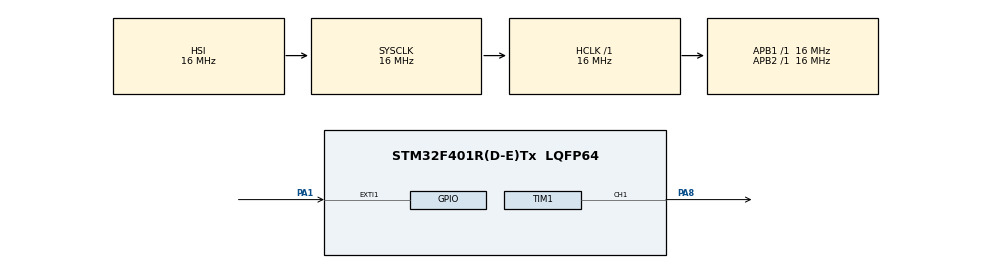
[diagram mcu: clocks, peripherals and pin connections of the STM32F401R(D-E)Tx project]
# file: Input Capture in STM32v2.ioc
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Mcu.Family=STM32F4
Mcu.Name=STM32F401R(D-E)Tx
Mcu.Package=LQFP64
NVIC.EXTI1_IRQn=true\:0\:0\:false\:false\:true\:true\:true\:true
NVIC.PriorityGroup=NVIC_PRIORITYGROUP_4
NVIC.TIM2_IRQn=true\:0\:0\:false\:false\:true\:true\:true\:true
PA1.GPIO_PuPd=GPIO_PULLDOWN
PA1.Signal=GPXTI1
PA8.Signal=S_TIM1_CH1
ProjectManager.HeapSize=0x200
ProjectManager.StackSize=0x400
ProjectManager.TargetToolchain=STM32CubeIDE
RCC.AHBFreq_Value=16000000
RCC.APB1Freq_Value=16000000
RCC.APB1TimFreq_Value=16000000
RCC.APB2Freq_Value=16000000
RCC.APB2TimFreq_Value=16000000
RCC.CortexFreq_Value=16000000
RCC.HCLKFreq_Value=16000000
RCC.HSE_VALUE=25000000
RCC.HSI_VALUE=16000000
RCC.LSE_VALUE=32768
RCC.SYSCLKFreq_VALUE=16000000
RCC.VCOOutputFreq_Value=192000000
SH.S_TIM1_CH1.0=TIM1_CH1,PWM Generation1 CH1
TIM1.Channel-PWM\ Generation1\ CH1=TIM_CHANNEL_1
TIM1.Period=100-1
TIM1.Prescaler=16-1
TIM2.Period=9999
TIM2.Prescaler=1600-1
VP_TIM1_VS_ClockSourceINT.Mode=Internal
VP_TIM2_VS_ClockSourceINT.Mode=Internal
board=custom

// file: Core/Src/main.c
/* USER CODE BEGIN Header */
/**
  ******************************************************************************
  * @file           : main.c
  * @brief          : Main program body
  ******************************************************************************
  * @attention
  *
  * Copyright (c) 2023 STMicroelectronics.
  * All rights reserved.
  *
  * This software is licensed under terms that can be found in the LICENSE file
  * in the root directory of this software component.
  * If no LICENSE file comes with this software, it is provided AS-IS.
  *
  ******************************************************************************
  */
/* USER CODE END Header */
#include "main.h"

TIM_HandleTypeDef htim1;
TIM_HandleTypeDef htim2;

/* USER CODE BEGIN PV */
uint32_t count = 0;

/* USER CODE END PV */

void SystemClock_Config(void);
static void MX_GPIO_Init(void);
static void MX_TIM1_Init(void);
static void MX_TIM2_Init(void);

/* USER CODE BEGIN 0 */
void HAL_TIM_PeriodElapsedCallback(TIM_HandleTypeDef *htim){

	if(htim == &htim2){
		HAL_NVIC_DisableIRQ(EXTI1_IRQn);
	}
}

__weak void HAL_GPIO_EXTI_Callback(uint16_t GPIO_Pin){
	if(GPIO_Pin == GPIO_PIN_1){
	count++;
	}
}

/* USER CODE END 0 */

int main(void)
{

  /* MCU Configuration--------------------------------------------------------*/

  /* Reset of all peripherals, Initializes the Flash interface and the Systick. */
  HAL_Init();

  /* Configure the system clock */
  SystemClock_Config();

  /* Initialize all configured peripherals */
  MX_GPIO_Init();
  MX_TIM1_Init();
  MX_TIM2_Init();
  /* USER CODE BEGIN 2 */
  TIM1->CCR1 = 50;
  HAL_TIM_PWM_Start(&htim1, TIM_CHANNEL_1);
  HAL_Delay(1000);
  HAL_TIM_Base_Start_IT(&htim2);
  HAL_NVIC_EnableIRQ(EXTI1_IRQn);
  //__HAL_TIM_DISABLE_IT(&htim2, TIM_IT_UPDATE);

  /* USER CODE END 2 */

  /* Infinite loop */
  while (1)
  {

  }
}

void SystemClock_Config(void)
{
  RCC_OscInitTypeDef RCC_OscInitStruct = {0};
  RCC_ClkInitTypeDef RCC_ClkInitStruct = {0};

  /** Configure the main internal regulator output voltage
  */
  __HAL_RCC_PWR_CLK_ENABLE();
  __HAL_PWR_VOLTAGESCALING_CONFIG(PWR_REGULATOR_VOLTAGE_SCALE2);

  /** Initializes the RCC Oscillators according to the specified parameters
  * in the RCC_OscInitTypeDef structure.
  */
  RCC_OscInitStruct.OscillatorType = RCC_OSCILLATORTYPE_HSI;
  RCC_OscInitStruct.HSIState = RCC_HSI_ON;
  RCC_OscInitStruct.HSICalibrationValue = RCC_HSICALIBRATION_DEFAULT;
  RCC_OscInitStruct.PLL.PLLState = RCC_PLL_NONE;
  if (HAL_RCC_OscConfig(&RCC_OscInitStruct) != HAL_OK)
  {
    Error_Handler();
  }

  /** Initializes the CPU, AHB and APB buses clocks
  */
  RCC_ClkInitStruct.ClockType = RCC_CLOCKTYPE_HCLK|RCC_CLOCKTYPE_SYSCLK
                              |RCC_CLOCKTYPE_PCLK1|RCC_CLOCKTYPE_PCLK2;
  RCC_ClkInitStruct.SYSCLKSource = RCC_SYSCLKSOURCE_HSI;
  RCC_ClkInitStruct.AHBCLKDivider = RCC_SYSCLK_DIV1;
  RCC_ClkInitStruct.APB1CLKDivider = RCC_HCLK_DIV1;
  RCC_ClkInitStruct.APB2CLKDivider = RCC_HCLK_DIV1;

  if (HAL_RCC_ClockConfig(&RCC_ClkInitStruct, FLASH_LATENCY_0) != HAL_OK)
  {
    Error_Handler();
  }
}

static void MX_TIM1_Init(void)
{

  TIM_ClockConfigTypeDef sClockSourceConfig = {0};
  TIM_MasterConfigTypeDef sMasterConfig = {0};
  TIM_OC_InitTypeDef sConfigOC = {0};
  TIM_BreakDeadTimeConfigTypeDef sBreakDeadTimeConfig = {0};

  htim1.Instance = TIM1;
  htim1.Init.Prescaler = 1-1;
  htim1.Init.CounterMode = TIM_COUNTERMODE_UP;
  htim1.Init.Period = 81-1;
  htim1.Init.ClockDivision = TIM_CLOCKDIVISION_DIV1;
  htim1.Init.RepetitionCounter = 0;
  htim1.Init.AutoReloadPreload = TIM_AUTORELOAD_PRELOAD_DISABLE;
  if (HAL_TIM_Base_Init(&htim1) != HAL_OK)
  {
    Error_Handler();
  }
  sClockSourceConfig.ClockSource = TIM_CLOCKSOURCE_INTERNAL;
  if (HAL_TIM_ConfigClockSource(&htim1, &sClockSourceConfig) != HAL_OK)
  {
    Error_Handler();
  }
  if (HAL_TIM_PWM_Init(&htim1) != HAL_OK)
  {
    Error_Handler();
  }
  sMasterConfig.MasterOutputTrigger = TIM_TRGO_RESET;
  sMasterConfig.MasterSlaveMode = TIM_MASTERSLAVEMODE_DISABLE;
  if (HAL_TIMEx_MasterConfigSynchronization(&htim1, &sMasterConfig) != HAL_OK)
  {
    Error_Handler();
  }
  sConfigOC.OCMode = TIM_OCMODE_PWM1;
  sConfigOC.Pulse = 0;
  sConfigOC.OCPolarity = TIM_OCPOLARITY_HIGH;
  sConfigOC.OCNPolarity = TIM_OCNPOLARITY_HIGH;
  sConfigOC.OCFastMode = TIM_OCFAST_DISABLE;
  sConfigOC.OCIdleState = TIM_OCIDLESTATE_RESET;
  sConfigOC.OCNIdleState = TIM_OCNIDLESTATE_RESET;
  if (HAL_TIM_PWM_ConfigChannel(&htim1, &sConfigOC, TIM_CHANNEL_1) != HAL_OK)
  {
    Error_Handler();
  }
  sBreakDeadTimeConfig.OffStateRunMode = TIM_OSSR_DISABLE;
  sBreakDeadTimeConfig.OffStateIDLEMode = TIM_OSSI_DISABLE;
  sBreakDeadTimeConfig.LockLevel = TIM_LOCKLEVEL_OFF;
  sBreakDeadTimeConfig.DeadTime = 0;
  sBreakDeadTimeConfig.BreakState = TIM_BREAK_DISABLE;
  sBreakDeadTimeConfig.BreakPolarity = TIM_BREAKPOLARITY_HIGH;
  sBreakDeadTimeConfig.AutomaticOutput = TIM_AUTOMATICOUTPUT_DISABLE;
  if (HAL_TIMEx_ConfigBreakDeadTime(&htim1, &sBreakDeadTimeConfig) != HAL_OK)
  {
    Error_Handler();
  }
  HAL_TIM_MspPostInit(&htim1);

}

static void MX_TIM2_Init(void)
{

  TIM_ClockConfigTypeDef sClockSourceConfig = {0};
  TIM_MasterConfigTypeDef sMasterConfig = {0};

  htim2.Instance = TIM2;
  htim2.Init.Prescaler = 1600-1;
  htim2.Init.CounterMode = TIM_COUNTERMODE_UP;
  htim2.Init.Period = 9999;
  htim2.Init.ClockDivision = TIM_CLOCKDIVISION_DIV1;
  htim2.Init.AutoReloadPreload = TIM_AUTORELOAD_PRELOAD_DISABLE;
  if (HAL_TIM_Base_Init(&htim2) != HAL_OK)
  {
    Error_Handler();
  }
  sClockSourceConfig.ClockSource = TIM_CLOCKSOURCE_INTERNAL;
  if (HAL_TIM_ConfigClockSource(&htim2, &sClockSourceConfig) != HAL_OK)
  {
    Error_Handler();
  }
  sMasterConfig.MasterOutputTrigger = TIM_TRGO_RESET;
  sMasterConfig.MasterSlaveMode = TIM_MASTERSLAVEMODE_DISABLE;
  if (HAL_TIMEx_MasterConfigSynchronization(&htim2, &sMasterConfig) != HAL_OK)
  {
    Error_Handler();
  }

}

static void MX_GPIO_Init(void)
{
  GPIO_InitTypeDef GPIO_InitStruct = {0};

  /* GPIO Ports Clock Enable */
  __HAL_RCC_GPIOA_CLK_ENABLE();

  /*Configure GPIO pin : PA1 */
  GPIO_InitStruct.Pin = GPIO_PIN_1;
  GPIO_InitStruct.Mode = GPIO_MODE_IT_RISING;
  GPIO_InitStruct.Pull = GPIO_NOPULL;
  HAL_GPIO_Init(GPIOA, &GPIO_InitStruct);

  /* EXTI interrupt init*/
  HAL_NVIC_SetPriority(EXTI1_IRQn, 1, 0);
  HAL_NVIC_DisableIRQ(EXTI1_IRQn);

}

void Error_Handler(void)
{
  __disable_irq();
  while (1)
  {
  }
}
